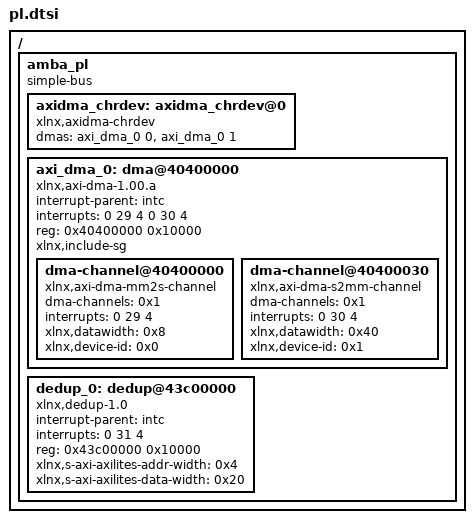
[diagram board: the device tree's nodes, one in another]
/*
 * CAUTION: This file is automatically generated by Xilinx.
 * Version: HSI 2016.2
 * Today is: Fri Dec  2 11:22:50 2016
*/


/ {
	amba_pl: amba_pl {
		#address-cells = <1>;
		#size-cells = <1>;
		compatible = "simple-bus";
		ranges ;

        axidma_chrdev: axidma_chrdev@0 {
            compatible = "xlnx,axidma-chrdev";
            dmas = <&axi_dma_0 0 &axi_dma_0 1>;
            dma-names = "tx_channel", "rx_channel";
        };

		axi_dma_0: dma@40400000 {
			#dma-cells = <1>;
			compatible = "xlnx,axi-dma-1.00.a";
			interrupt-parent = <&intc>;
			interrupts = <0 29 4 0 30 4>;
			reg = <0x40400000 0x10000>;
			xlnx,include-sg ;
			dma-channel@40400000 {
				compatible = "xlnx,axi-dma-mm2s-channel";
				dma-channels = <0x1>;
				interrupts = <0 29 4>;
				xlnx,datawidth = <0x8>;
				xlnx,device-id = <0x0>;
			};
			dma-channel@40400030 {
				compatible = "xlnx,axi-dma-s2mm-channel";
				dma-channels = <0x1>;
				interrupts = <0 30 4>;
				xlnx,datawidth = <0x40>;
				xlnx,device-id = <0x1>;
			};
		};
		dedup_0: dedup@43c00000 {
			compatible = "xlnx,dedup-1.0";
			interrupt-parent = <&intc>;
			interrupts = <0 31 4>;
			reg = <0x43c00000 0x10000>;
			xlnx,s-axi-axilites-addr-width = <0x4>;
			xlnx,s-axi-axilites-data-width = <0x20>;
		};
	};
};
